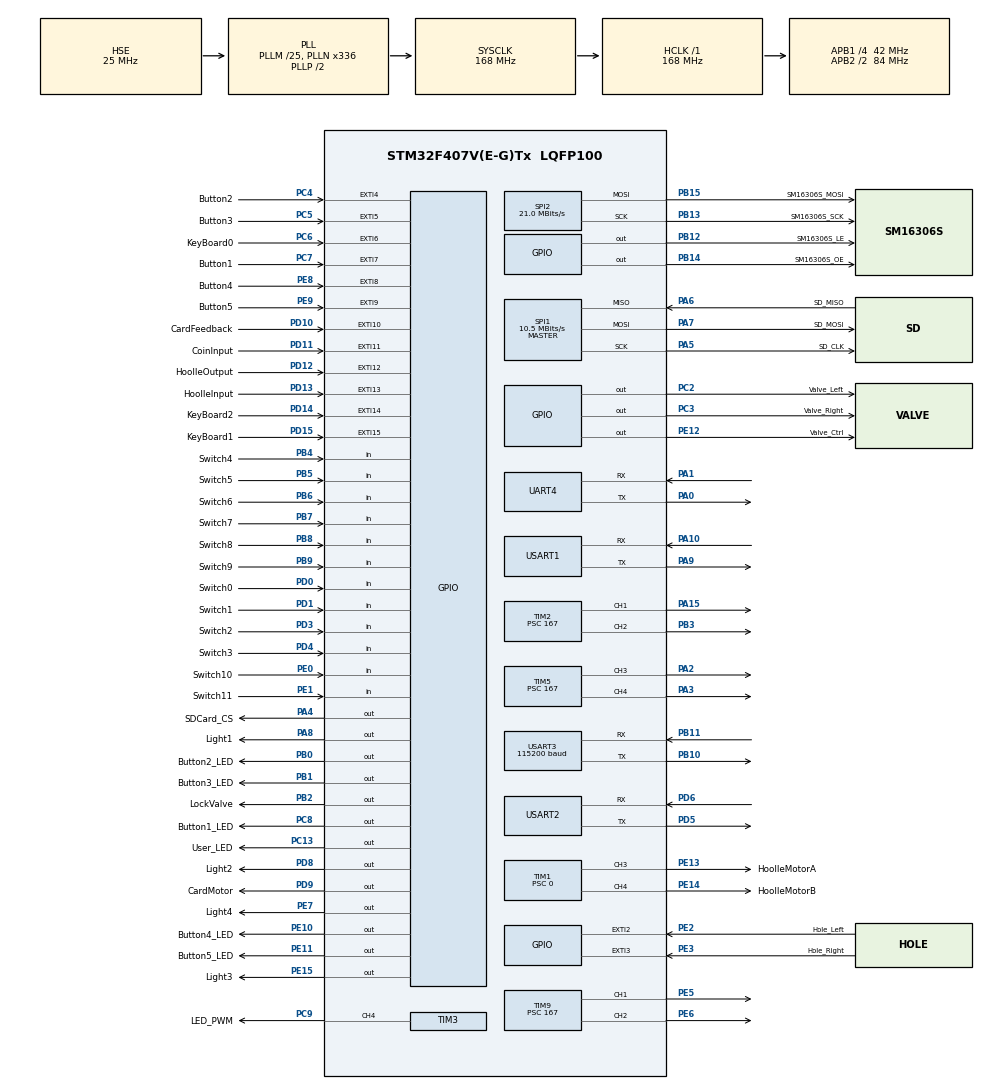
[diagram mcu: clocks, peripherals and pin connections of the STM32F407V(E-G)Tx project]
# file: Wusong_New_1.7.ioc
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Dma.Request0=TIM3_CH4/UP
Dma.TIM3_CH4/UP.0.Direction=DMA_MEMORY_TO_PERIPH
Dma.TIM3_CH4/UP.0.FIFOMode=DMA_FIFOMODE_DISABLE
Dma.TIM3_CH4/UP.0.Instance=DMA1_Stream2
Dma.TIM3_CH4/UP.0.MemDataAlignment=DMA_MDATAALIGN_HALFWORD
Dma.TIM3_CH4/UP.0.MemInc=DMA_MINC_ENABLE
Dma.TIM3_CH4/UP.0.Mode=DMA_NORMAL
Dma.TIM3_CH4/UP.0.PeriphDataAlignment=DMA_PDATAALIGN_HALFWORD
Dma.TIM3_CH4/UP.0.PeriphInc=DMA_PINC_DISABLE
Dma.TIM3_CH4/UP.0.Priority=DMA_PRIORITY_LOW
IWDG.Prescaler=IWDG_PRESCALER_32
IWDG.Reload=3000
Mcu.Family=STM32F4
Mcu.Name=STM32F407V(E-G)Tx
Mcu.Package=LQFP100
NVIC.DMA1_Stream2_IRQn=true\:0\:0\:false\:false\:true\:false\:true\:true
NVIC.EXTI15_10_IRQn=true\:1\:0\:true\:false\:true\:true\:true\:true
NVIC.EXTI2_IRQn=true\:1\:0\:true\:false\:true\:true\:true\:true
NVIC.EXTI3_IRQn=true\:1\:0\:true\:false\:true\:true\:true\:true
NVIC.EXTI4_IRQn=true\:1\:0\:true\:false\:true\:true\:true\:true
NVIC.EXTI9_5_IRQn=true\:1\:0\:true\:false\:true\:true\:true\:true
NVIC.PriorityGroup=NVIC_PRIORITYGROUP_4
NVIC.UART4_IRQn=true\:0\:0\:false\:false\:true\:true\:true\:true
NVIC.USART1_IRQn=true\:0\:0\:true\:false\:true\:false\:true\:true
NVIC.USART3_IRQn=true\:2\:0\:true\:false\:true\:true\:true\:true
PA0-WKUP.Mode=Asynchronous
PA0-WKUP.Signal=UART4_TX
PA1.GPIO_PuPd=GPIO_PULLDOWN
PA1.Mode=Asynchronous
PA1.Signal=UART4_RX
PA10.GPIO_PuPd=GPIO_PULLDOWN
PA10.Mode=Asynchronous
PA10.Signal=USART1_RX
PA13.Mode=Serial_Wire
PA13.Signal=SYS_JTMS-SWDIO
PA14.Mode=Serial_Wire
PA14.Signal=SYS_JTCK-SWCLK
PA15.Signal=S_TIM2_CH1_ETR
PA2.Signal=S_TIM5_CH3
PA3.Signal=S_TIM5_CH4
PA4.GPIO_Label=SDCard_CS
PA4.Signal=GPIO_Output
PA5.GPIO_Label=SD_CLK
PA5.Mode=Full_Duplex_Master
PA5.Signal=SPI1_SCK
PA6.GPIO_Label=SD_MISO
PA6.Mode=Full_Duplex_Master
PA6.Signal=SPI1_MISO
PA7.GPIO_Label=SD_MOSI
PA7.Mode=Full_Duplex_Master
PA7.Signal=SPI1_MOSI
PA8.GPIO_Label=Light1
PA8.GPIO_Speed=GPIO_SPEED_FREQ_HIGH
PA8.Signal=GPIO_Output
PA9.Mode=Asynchronous
PA9.Signal=USART1_TX
PB0.GPIO_Label=Button2_LED
PB0.Signal=GPIO_Output
PB1.GPIO_Label=Button3_LED
PB1.Signal=GPIO_Output
PB10.Mode=Asynchronous
PB10.Signal=USART3_TX
PB11.GPIO_PuPd=GPIO_PULLDOWN
PB11.Mode=Asynchronous
PB11.Signal=USART3_RX
PB12.GPIO_Label=SM16306S_LE
PB12.Signal=GPIO_Output
PB13.GPIO_Label=SM16306S_SCK
PB13.Mode=TX_Only_Simplex_Unidirect_Master
PB13.Signal=SPI2_SCK
PB14.GPIO_Label=SM16306S_OE
PB14.Signal=GPIO_Output
PB15.GPIO_Label=SM16306S_MOSI
PB15.Mode=TX_Only_Simplex_Unidirect_Master
PB15.Signal=SPI2_MOSI
PB2.GPIO_Label=LockValve
PB2.GPIO_Speed=GPIO_SPEED_FREQ_HIGH
PB2.Signal=GPIO_Output
PB3.Signal=S_TIM2_CH2
PB4.GPIO_Label=Switch4
PB4.GPIO_PuPd=GPIO_PULLUP
PB4.Signal=GPIO_Input
PB5.GPIO_Label=Switch5
PB5.GPIO_PuPd=GPIO_PULLUP
PB5.Signal=GPIO_Input
PB6.GPIO_Label=Switch6
PB6.GPIO_PuPd=GPIO_PULLUP
PB6.Signal=GPIO_Input
PB7.GPIO_Label=Switch7
PB7.GPIO_PuPd=GPIO_PULLUP
PB7.Signal=GPIO_Input
PB8.GPIO_Label=Switch8
PB8.GPIO_PuPd=GPIO_PULLUP
PB8.Signal=GPIO_Input
PB9.GPIO_Label=Switch9
PB9.GPIO_PuPd=GPIO_PULLUP
PB9.Signal=GPIO_Input
PC13-ANTI_TAMP.GPIO_Label=User_LED
PC13-ANTI_TAMP.Signal=GPIO_Output
PC2.GPIO_Label=Valve_Left
PC2.PinState=GPIO_PIN_RESET
PC2.Signal=GPIO_Output
PC3.GPIO_Label=Valve_Right
PC3.PinState=GPIO_PIN_RESET
PC3.Signal=GPIO_Output
PC4.GPIO_Label=Button2
PC4.GPIO_ModeDefaultEXTI=GPIO_MODE_IT_RISING_FALLING
PC4.GPIO_PuPd=GPIO_NOPULL
PC4.Signal=GPXTI4
PC5.GPIO_Label=Button3
PC5.GPIO_ModeDefaultEXTI=GPIO_MODE_IT_RISING_FALLING
PC5.Signal=GPXTI5
PC6.GPIO_Label=KeyBoard0
PC6.GPIO_ModeDefaultEXTI=GPIO_MODE_IT_RISING_FALLING
PC6.GPIO_PuPd=GPIO_PULLUP
PC6.Signal=GPXTI6
PC7.GPIO_Label=Button1
PC7.GPIO_ModeDefaultEXTI=GPIO_MODE_IT_RISING_FALLING
PC7.Signal=GPXTI7
PC8.GPIO_Label=Button1_LED
PC8.Signal=GPIO_Output
PC9.GPIO_Label=LED_PWM
PC9.GPIO_Speed=GPIO_SPEED_FREQ_HIGH
PC9.Signal=S_TIM3_CH4
PD0.GPIO_Label=Switch0
PD0.GPIO_PuPd=GPIO_PULLUP
PD0.Signal=GPIO_Input
PD1.GPIO_Label=Switch1
PD1.GPIO_PuPd=GPIO_PULLUP
PD1.Signal=GPIO_Input
PD10.GPIO_Label=CardFeedback
PD10.Signal=GPXTI10
PD11.GPIO_Label=CoinInput
PD11.GPIO_ModeDefaultEXTI=GPIO_MODE_IT_FALLING
PD11.Signal=GPXTI11
PD12.GPIO_Label=HoolleOutput
PD12.GPIO_ModeDefaultEXTI=GPIO_MODE_IT_RISING_FALLING
PD12.Signal=GPXTI12
PD13.GPIO_Label=HoolleInput
PD13.GPIO_ModeDefaultEXTI=GPIO_MODE_IT_FALLING
PD13.Signal=GPXTI13
PD14.GPIO_Label=KeyBoard2
PD14.GPIO_ModeDefaultEXTI=GPIO_MODE_IT_RISING_FALLING
PD14.GPIO_PuPd=GPIO_PULLUP
PD14.Signal=GPXTI14
PD15.GPIO_Label=KeyBoard1
PD15.GPIO_ModeDefaultEXTI=GPIO_MODE_IT_RISING_FALLING
PD15.GPIO_PuPd=GPIO_PULLUP
PD15.Signal=GPXTI15
PD3.GPIO_Label=Switch2
PD3.GPIO_PuPd=GPIO_PULLUP
PD3.Signal=GPIO_Input
PD4.GPIO_Label=Switch3
PD4.GPIO_PuPd=GPIO_PULLUP
PD4.Signal=GPIO_Input
PD5.Mode=Asynchronous
PD5.Signal=USART2_TX
PD6.GPIO_PuPd=GPIO_PULLDOWN
PD6.Mode=Asynchronous
PD6.Signal=USART2_RX
PD8.GPIO_Label=Light2
PD8.GPIO_Speed=GPIO_SPEED_FREQ_HIGH
PD8.Signal=GPIO_Output
PD9.GPIO_Label=CardMotor
PD9.Signal=GPIO_Output
PE0.GPIO_Label=Switch10
PE0.GPIO_PuPd=GPIO_PULLUP
PE0.Signal=GPIO_Input
PE1.GPIO_Label=Switch11
PE1.GPIO_PuPd=GPIO_PULLUP
PE1.Signal=GPIO_Input
PE10.GPIO_Label=Button4_LED
PE10.Signal=GPIO_Output
PE11.GPIO_Label=Button5_LED
PE11.Signal=GPIO_Output
PE12.GPIO_Label=Valve_Ctrl
PE12.Signal=GPIO_Output
PE13.GPIO_Label=HoolleMotorA
PE13.Signal=S_TIM1_CH3
PE14.GPIO_Label=HoolleMotorB
PE14.Signal=S_TIM1_CH4
PE15.GPIO_Label=Light3
PE15.GPIO_Speed=GPIO_SPEED_FREQ_HIGH
PE15.Signal=GPIO_Output
PE2.GPIO_Label=Hole_Left
PE2.GPIO_ModeDefaultEXTI=GPIO_MODE_IT_RISING
PE2.Signal=GPXTI2
PE3.GPIO_Label=Hole_Right
PE3.GPIO_ModeDefaultEXTI=GPIO_MODE_IT_RISING
PE3.Signal=GPXTI3
PE5.Signal=S_TIM9_CH1
PE6.Signal=S_TIM9_CH2
PE7.GPIO_Label=Light4
PE7.GPIO_Speed=GPIO_SPEED_FREQ_HIGH
PE7.Signal=GPIO_Output
PE8.GPIO_Label=Button4
PE8.GPIO_ModeDefaultEXTI=GPIO_MODE_IT_RISING_FALLING
PE8.Signal=GPXTI8
PE9.GPIO_Label=Button5
PE9.GPIO_ModeDefaultEXTI=GPIO_MODE_IT_RISING_FALLING
PE9.Signal=GPXTI9
PH0-OSC_IN.Mode=HSE-External-Oscillator
PH0-OSC_IN.Signal=RCC_OSC_IN
PH1-OSC_OUT.Mode=HSE-External-Oscillator
PH1-OSC_OUT.Signal=RCC_OSC_OUT
ProjectManager.HeapSize=0x1500
ProjectManager.StackSize=0x1500
ProjectManager.TargetToolchain=MDK-ARM V5.32
RCC.48MHZClocksFreq_Value=84000000
RCC.AHBFreq_Value=168000000
RCC.APB1CLKDivider=RCC_HCLK_DIV4
RCC.APB1Freq_Value=42000000
RCC.APB1TimFreq_Value=84000000
RCC.APB2CLKDivider=RCC_HCLK_DIV2
RCC.APB2Freq_Value=84000000
RCC.APB2TimFreq_Value=168000000
RCC.CortexFreq_Value=168000000
RCC.HCLKFreq_Value=168000000
RCC.HSE_Timout=1500
RCC.HSE_VALUE=25000000
RCC.HSI_VALUE=16000000
RCC.LSE_VALUE=32768
RCC.PLLM=25
RCC.PLLN=336
RCC.PLLSourceVirtual=RCC_PLLSOURCE_HSE
RCC.SYSCLKFreq_VALUE=168000000
RCC.SYSCLKSource=RCC_SYSCLKSOURCE_PLLCLK
RCC.VCOOutputFreq_Value=336000000
SH.S_TIM1_CH3.0=TIM1_CH3,PWM Generation3 CH3
SH.S_TIM1_CH4.0=TIM1_CH4,PWM Generation4 CH4
SH.S_TIM2_CH1_ETR.0=TIM2_CH1,PWM Generation1 CH1
SH.S_TIM2_CH2.0=TIM2_CH2,PWM Generation2 CH2
SH.S_TIM3_CH4.0=TIM3_CH4,PWM Generation4 CH4
SH.S_TIM5_CH3.0=TIM5_CH3,PWM Generation3 CH3
SH.S_TIM5_CH4.0=TIM5_CH4,PWM Generation4 CH4
SH.S_TIM9_CH1.0=TIM9_CH1,PWM Generation1 CH1
SH.S_TIM9_CH2.0=TIM9_CH2,PWM Generation2 CH2
SPI1.BaudRatePrescaler=SPI_BAUDRATEPRESCALER_8
SPI1.CalculateBaudRate=10.5 MBits/s
SPI1.Direction=SPI_DIRECTION_2LINES
SPI1.Mode=SPI_MODE_MASTER
SPI1.VirtualType=VM_MASTER
SPI2.CalculateBaudRate=21.0 MBits/s
SPI2.Direction=SPI_DIRECTION_2LINES
SPI2.Mode=SPI_MODE_MASTER
SPI2.VirtualType=VM_MASTER
TIM1.AutoReloadPreload=TIM_AUTORELOAD_PRELOAD_ENABLE
TIM1.Channel-PWM\ Generation3\ CH3=TIM_CHANNEL_3
TIM1.Channel-PWM\ Generation4\ CH4=TIM_CHANNEL_4
TIM1.Period=65535
TIM1.Prescaler=0
TIM2.AutoReloadPreload=TIM_AUTORELOAD_PRELOAD_ENABLE
TIM2.Channel-PWM\ Generation1\ CH1=TIM_CHANNEL_1
TIM2.Channel-PWM\ Generation2\ CH2=TIM_CHANNEL_2
TIM2.Period=999
TIM2.Prescaler=167
TIM3.AutoReloadPreload=TIM_AUTORELOAD_PRELOAD_ENABLE
TIM3.Channel-PWM\ Generation4\ CH4=TIM_CHANNEL_4
TIM3.Period=14
TIM3.Prescaler=6
TIM5.AutoReloadPreload=TIM_AUTORELOAD_PRELOAD_ENABLE
TIM5.Channel-PWM\ Generation3\ CH3=TIM_CHANNEL_3
TIM5.Channel-PWM\ Generation4\ CH4=TIM_CHANNEL_4
TIM5.Period=999
TIM5.Prescaler=167
TIM7.AutoReloadPreload=TIM_AUTORELOAD_PRELOAD_ENABLE
TIM7.Prescaler=83
TIM9.AutoReloadPreload=TIM_AUTORELOAD_PRELOAD_ENABLE
TIM9.Channel-PWM\ Generation1\ CH1=TIM_CHANNEL_1
TIM9.Channel-PWM\ Generation2\ CH2=TIM_CHANNEL_2
TIM9.Period=999
TIM9.Prescaler=167
UART4.VirtualMode=Asynchronous
USART1.VirtualMode=VM_ASYNC
USART2.VirtualMode=VM_ASYNC
USART3.BaudRate=115200
USART3.VirtualMode=VM_ASYNC
VP_IWDG_VS_IWDG.Mode=IWDG_Activate
VP_TIM1_VS_ClockSourceINT.Mode=Internal
VP_TIM2_VS_ClockSourceINT.Mode=Internal
VP_TIM3_VS_ClockSourceINT.Mode=Internal
VP_TIM5_VS_ClockSourceINT.Mode=Internal
VP_TIM7_VS_ClockSourceINT.Mode=Enable_Timer
VP_TIM9_VS_ClockSourceINT.Mode=Internal
board=custom

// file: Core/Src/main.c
/* USER CODE BEGIN Header */
/**
  ******************************************************************************
  * @file           : main.c
  * @brief          : Main program body
  ******************************************************************************
  * @attention
  *
  * Copyright (c) 2026 STMicroelectronics.
  * All rights reserved.
  *
  * This software is licensed under terms that can be found in the LICENSE file
  * in the root directory of this software component.
  * If no LICENSE file comes with this software, it is provided AS-IS.
  *
  ******************************************************************************
  */
/* USER CODE END Header */
#include "main.h"
#include "dma.h"
#include "iwdg.h"
#include "spi.h"
#include "tim.h"
#include "usart.h"
#include "gpio.h"

/* USER CODE BEGIN Includes */
#include "MainTask.h"
/* USER CODE END Includes */

/* USER CODE BEGIN PD */
#define APP_VECTOR_TABLE_ADDR 0x0800C000U
/* USER CODE END PD */

void SystemClock_Config(void);

int main(void)
{

  /* USER CODE BEGIN 1 */
  SCB->VTOR = APP_VECTOR_TABLE_ADDR;
  __DSB();
  __ISB();
  __enable_irq();
  /* USER CODE END 1 */

  /* MCU Configuration--------------------------------------------------------*/

  /* Reset of all peripherals, Initializes the Flash interface and the Systick. */
  HAL_Init();

  /* Configure the system clock */
  SystemClock_Config();

  /* USER CODE BEGIN SysInit */
  HAL_Delay(1000);
  /* USER CODE END SysInit */

  /* Initialize all configured peripherals */
  MX_GPIO_Init();
  MX_DMA_Init();
  MX_SPI1_Init();
  MX_TIM1_Init();
  MX_USART1_UART_Init();
  MX_SPI2_Init();
  MX_TIM2_Init();
  MX_TIM3_Init();
  MX_USART2_UART_Init();
  MX_USART3_UART_Init();
  MX_UART4_Init();
  MX_IWDG_Init();
  MX_TIM5_Init();
  MX_TIM9_Init();
  MX_TIM7_Init();
  /* USER CODE BEGIN 2 */
  Main_Init();
  /* USER CODE END 2 */

  /* Infinite loop */
  /* USER CODE BEGIN WHILE */
  while (1)
  {
    Main_Task();
    /* USER CODE END WHILE */

  }
}

void SystemClock_Config(void)
{
  RCC_OscInitTypeDef RCC_OscInitStruct = {0};
  RCC_ClkInitTypeDef RCC_ClkInitStruct = {0};

  /** Configure the main internal regulator output voltage
  */
  __HAL_RCC_PWR_CLK_ENABLE();
  __HAL_PWR_VOLTAGESCALING_CONFIG(PWR_REGULATOR_VOLTAGE_SCALE1);

  /** Initializes the RCC Oscillators according to the specified parameters
  * in the RCC_OscInitTypeDef structure.
  */
  RCC_OscInitStruct.OscillatorType = RCC_OSCILLATORTYPE_LSI|RCC_OSCILLATORTYPE_HSE;
  RCC_OscInitStruct.HSEState = RCC_HSE_ON;
  RCC_OscInitStruct.LSIState = RCC_LSI_ON;
  RCC_OscInitStruct.PLL.PLLState = RCC_PLL_ON;
  RCC_OscInitStruct.PLL.PLLSource = RCC_PLLSOURCE_HSE;
  RCC_OscInitStruct.PLL.PLLM = 25;
  RCC_OscInitStruct.PLL.PLLN = 336;
  RCC_OscInitStruct.PLL.PLLP = RCC_PLLP_DIV2;
  RCC_OscInitStruct.PLL.PLLQ = 4;
  if (HAL_RCC_OscConfig(&RCC_OscInitStruct) != HAL_OK)
  {
    Error_Handler();
  }

  /** Initializes the CPU, AHB and APB buses clocks
  */
  RCC_ClkInitStruct.ClockType = RCC_CLOCKTYPE_HCLK|RCC_CLOCKTYPE_SYSCLK
                              |RCC_CLOCKTYPE_PCLK1|RCC_CLOCKTYPE_PCLK2;
  RCC_ClkInitStruct.SYSCLKSource = RCC_SYSCLKSOURCE_PLLCLK;
  RCC_ClkInitStruct.AHBCLKDivider = RCC_SYSCLK_DIV1;
  RCC_ClkInitStruct.APB1CLKDivider = RCC_HCLK_DIV4;
  RCC_ClkInitStruct.APB2CLKDivider = RCC_HCLK_DIV2;

  if (HAL_RCC_ClockConfig(&RCC_ClkInitStruct, FLASH_LATENCY_5) != HAL_OK)
  {
    Error_Handler();
  }
}

void Error_Handler(void)
{
  __disable_irq();
  while (1)
  {
  }
}
